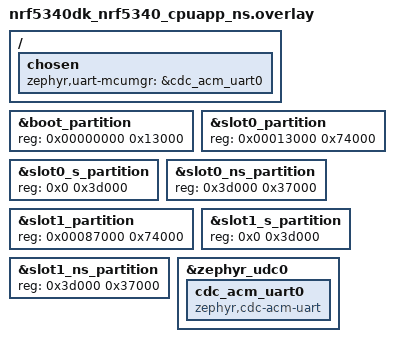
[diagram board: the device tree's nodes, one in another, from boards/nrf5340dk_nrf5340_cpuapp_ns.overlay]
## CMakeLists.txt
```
# SPDX-License-Identifier: Apache-2.0

cmake_minimum_required(VERSION 3.20.0)

find_package(Zephyr REQUIRED HINTS $ENV{ZEPHYR_BASE})
project(devacademy)

# STEP 6.1 - Include common files from Zephyr USB samples
include(${ZEPHYR_BASE}/samples/subsys/usb/common/common.cmake)

target_sources(app PRIVATE src/main.c)
```

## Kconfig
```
source "samples/subsys/usb/common/Kconfig.sample_usbd"

source "Kconfig.zephyr"
```

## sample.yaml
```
sample:
  description: nRF Connect SDK Intermediate Course by Nordic Developer Academy (https://academy.nordicsemi.com/)
  name: nRF Connect SDK Intermediate Course - Lesson 9 Exercise 4 Solution
  
common: 
    sysbuild: true
    harness: console
    harness_config:
      type: one_line
      regex:
        - "USB device support enabled"
    
tests:
  ncs_inter.l9.e4.sol:
    integration_platforms: 
      - nrf52833dk/nrf52833
      - nrf52840dk/nrf52840
      - nrf5340dk/nrf5340/cpuapp
      - nrf5340dk/nrf5340/cpuapp/ns
    platform_allow:
      - nrf52833dk/nrf52833
      - nrf52840dk/nrf52840
      - nrf5340dk/nrf5340/cpuapp
      - nrf5340dk/nrf5340/cpuapp/ns
    extra_args:
      - CONFIG_SAMPLE_USBD_PID=0x0001
      - CONFIG_SAMPLE_USBD_PRODUCT="USBD CDC ACM sample"

  ncs_inter.l9.e4.sol_lm20:
    integration_platforms: 
      - nrf54lm20dk/nrf54lm20a/cpuapp
    platform_allow:
      - nrf54lm20dk/nrf54lm20a/cpuapp        
```

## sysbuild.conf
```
# Add MCUboot
SB_CONFIG_BOOTLOADER_MCUBOOT=y
SB_CONFIG_MCUBOOT_USE_ALL_AVAILABLE_RAM=y

SB_CONFIG_PARTITION_MANAGER=n
```

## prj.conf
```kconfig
CONFIG_GPIO=y

# Enable MCUboot
CONFIG_BOOTLOADER_MCUBOOT=y

# Enable mcumgr DFU in application
CONFIG_MCUMGR=y

# Enable MCUMGR management for both OS and Images
CONFIG_MCUMGR_GRP_OS=y
CONFIG_MCUMGR_GRP_IMG=y

# Configure MCUMGR transport to UART
CONFIG_UART_MCUMGR=y
CONFIG_MCUMGR_TRANSPORT_UART=y


# Dependencies
# Configure dependencies for CONFIG_MCUMGR  
CONFIG_NET_BUF=y
CONFIG_ZCBOR=y
CONFIG_CRC=y

# Configure dependencies for CONFIG_MCUMGR_GRP_IMG  
CONFIG_FLASH=y
CONFIG_IMG_MANAGER=y

# Configure dependencies for CONFIG_IMG_MANAGER  
CONFIG_STREAM_FLASH=y
CONFIG_FLASH_MAP=y

# Configure dependencies for CONFIG_MCUMGR_TRANSPORT_UART 
CONFIG_BASE64=y

# STEP 5.3 - Enable USB subsystem
CONFIG_USB_DEVICE_STACK_NEXT=y
CONFIG_UART_USE_RUNTIME_CONFIGURE=y
CONFIG_UART_LINE_CTRL=y
CONFIG_USBD_CDC_ACM_CLASS=y


CONFIG_SAMPLE_USBD_PID=0x0001
CONFIG_SAMPLE_USBD_PRODUCT="USBD CDC ACM sample"
```

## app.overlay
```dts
/* STEP 5.2 - choose CDC ACM for mcumgr */
/ {
	chosen {
		zephyr,uart-mcumgr = &cdc_acm_uart0;
	};
};

/* STEP 5.1 - Configure CDC ACM */
&zephyr_udc0 {
	cdc_acm_uart0: cdc_acm_uart0 {
		compatible = "zephyr,cdc-acm-uart";
	};
};
```

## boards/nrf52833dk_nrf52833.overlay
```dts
/delete-node/ &slot1_partition;
/delete-node/ &slot0_partition;
/delete-node/ &storage_partition;

&flash0 {
	partitions {
		ranges;
		#address-cells = <1>;
		#size-cells = <1>;

		boot_partition: partition@0 {
			compatible = "zephyr,mapped-partition";
			label = "mcuboot";
			reg = <0x00000000 0x13000>;
		};

		slot0_partition: partition@13000 {
			compatible = "zephyr,mapped-partition";
			label = "image-0";
			reg = <0x00013000 0x17000>;
		};

		slot1_partition: partition@2a000 {
			compatible = "zephyr,mapped-partition";
			label = "image-1";
			reg = <0x0002a000 0x17000>;
		};

		storage_partition: partition@41000 {
			compatible = "zephyr,mapped-partition";
			label = "storage";
			reg = <0x00041000 0x00006000>;
		};
	};
};


/* STEP 5.2 - Choose CDC ACM for mcumgr */
/ {
	chosen {
		zephyr,uart-mcumgr = &cdc_acm_uart0;
	};
};

/* STEP 5.1 - Configure CDC ACM */
&zephyr_udc0 {
	cdc_acm_uart0: cdc_acm_uart0 {
		compatible = "zephyr,cdc-acm-uart";
	};
};
```

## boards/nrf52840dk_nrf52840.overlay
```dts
/delete-node/ &slot1_partition;
/delete-node/ &slot0_partition;
/delete-node/ &storage_partition;

&flash0 {
	partitions {
		ranges;
		#address-cells = <1>;
		#size-cells = <1>;

		boot_partition: partition@0 {
			compatible = "zephyr,mapped-partition";
			label = "mcuboot";
			reg = <0x00000000 0x00013000>;
		};

		slot0_partition: partition@13000 {
			compatible = "zephyr,mapped-partition";
			label = "image-0";
			reg = <0x00013000 0x00076000>;
		};

		slot1_partition: partition@89000 {
			compatible = "zephyr,mapped-partition";
			label = "image-1";
			reg = <0x00089000 0x00076000>;
		};

		/*
		 * The flash starting at 0x000f8000 and ending at
		 * 0x000fffff is reserved for use by the application.
		 */

		/*
		 * Storage partition will be used by FCB/LittleFS/NVS
		 * if enabled.
		 */
		storage_partition: partition@ff000 {
			compatible = "zephyr,mapped-partition";
			label = "storage";
			reg = <0x000ff000 0x00001000>;
		};
	};
};




/* STEP 5.2 - Choose CDC ACM for mcumgr */
/ {
	chosen {
		zephyr,uart-mcumgr = &cdc_acm_uart0;
	};
};

/* STEP 5.1 - Configure CDC ACM */
&zephyr_udc0 {
	cdc_acm_uart0: cdc_acm_uart0 {
		compatible = "zephyr,cdc-acm-uart";
	};
};
```

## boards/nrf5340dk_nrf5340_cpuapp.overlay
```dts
/delete-node/ &slot1_partition;
/delete-node/ &slot0_partition;
/delete-node/ &storage_partition;


&flash0 {
	partitions {
		ranges;
		#address-cells = <1>;
		#size-cells = <1>;

		boot_partition: partition@0 {
			compatible = "zephyr,mapped-partition";
			label = "mcuboot";
			reg = <0x00000000 0x13000>;
		};

		slot0_partition: partition@13000 {
			compatible = "zephyr,mapped-partition";
			label = "image-0";
			reg = <0x00013000 0x74000>;
		};

		slot1_partition: partition@87000 {
			compatible = "zephyr,mapped-partition";
			label = "image-1";
			reg = <0x00087000 0x74000>;
		};

	};
};


/ {
	chosen {
		zephyr,uart-mcumgr = &cdc_acm_uart0;
	};
};

&zephyr_udc0 {
	cdc_acm_uart0: cdc_acm_uart0 {
		compatible = "zephyr,cdc-acm-uart";
	};
};
```

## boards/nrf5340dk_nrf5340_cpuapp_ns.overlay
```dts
/delete-node/ &storage_partition;

&boot_partition {
	reg = <0x00000000 0x13000>;
};

&slot0_partition {
	reg = <0x00013000 0x74000>;
	ranges = <0x0 0x13000 0x74000>;
};

&slot0_s_partition {
	reg = <0x0 0x3d000>;
};

&slot0_ns_partition {
	reg = <0x3d000 0x37000>;
};

&slot1_partition {
	reg = <0x00087000 0x74000>;
	ranges = <0x0 0x87000 0x74000>;
};

&slot1_s_partition {
	reg = <0x0 0x3d000>;
};

&slot1_ns_partition {
	reg = <0x3d000 0x37000>;
};

/* STEP 5.2 - Choose CDC ACM for mcumgr */
/ {
	chosen {
		zephyr,uart-mcumgr = &cdc_acm_uart0;
	};
};

/* STEP 5.1 - Configure CDC ACM */
&zephyr_udc0 {
	cdc_acm_uart0: cdc_acm_uart0 {
		compatible = "zephyr,cdc-acm-uart";
	};
};
```

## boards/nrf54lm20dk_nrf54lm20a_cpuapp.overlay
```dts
/delete-node/ &boot_partition;
/delete-node/ &slot0_partition;
/delete-node/ &slot1_partition;

&cpuapp_rram {
    partitions {
        boot_partition: partition@0 {
            compatible = "zephyr,mapped-partition";
            label = "mcuboot";
            reg = <0x0 DT_SIZE_K(100)>;
        };

        slot0_partition: partition@19000 {
            compatible = "zephyr,mapped-partition";
            label = "image-0";
            reg = <0x19000 DT_SIZE_K(800)>;
        };

        slot1_partition: partition@e1000 {
            compatible = "zephyr,mapped-partition";
            label = "image-1";
            reg = <0xe1000 DT_SIZE_K(800)>;
        };
    };
};

/* CDC ACM for mcumgr (from app.overlay) */
/* STEP 5.2 - Choose CDC ACM for mcumgr */
/ {
    chosen {
        zephyr,uart-mcumgr = &cdc_acm_uart0;
    };
};

/* STEP 5.1 - Configure CDC ACM */
&zephyr_udc0 {
    cdc_acm_uart0: cdc_acm_uart0 {
        compatible = "zephyr,cdc-acm-uart";
    };
};
```

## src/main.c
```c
/*
 * Copyright (c) 2016 Intel Corporation
 *
 * SPDX-License-Identifier: Apache-2.0
 */

#include <zephyr/kernel.h>
#include <zephyr/drivers/gpio.h>

/* STEP 7.1 - Include header for USB */
#include <sample_usbd.h>

#include <zephyr/logging/log.h>
LOG_MODULE_REGISTER(usb_cdc, LOG_LEVEL_INF);

/* 1000 msec = 1 sec */

#define SLEEP_TIME_MS 1000

/* The devicetree node identifier for the "led0" alias. */
#define LED0_NODE DT_ALIAS(led0)

/*
 * A build error on this line means your board is unsupported.
 * See the sample documentation for information on how to fix this.
 */
static const struct gpio_dt_spec led = GPIO_DT_SPEC_GET(LED0_NODE, gpios);

/* STEP 7.2 - Create context for USB stack */
static struct usbd_context *sample_usbd;

/* STEP 7.3 - Create VBUS callback function */
static void sample_msg_cb(struct usbd_context *const ctx, const struct usbd_msg *msg)
{
    LOG_INF("USBD message: %s", usbd_msg_type_string(msg->type));

    if (usbd_can_detect_vbus(ctx)) {
        if (msg->type == USBD_MSG_VBUS_READY) {
            if (usbd_enable(ctx)) {
                LOG_ERR("Failed to enable device support");
            }
        }

        if (msg->type == USBD_MSG_VBUS_REMOVED) {
            if (usbd_disable(ctx)) {
                LOG_ERR("Failed to disable device support");
            }
        }
    }
}


int main(void)
{
    int ret;

    /* STEP 7.4 - Initialize usb device */
    sample_usbd = sample_usbd_init_device(sample_msg_cb);
    if (sample_usbd == NULL) {
        LOG_ERR("Failed to initialize USB device");
        return -ENODEV;
    }

    /* STEP 7.5 - Enable usb device in case vbus not detected */
    if (!usbd_can_detect_vbus(sample_usbd)) {
        ret = usbd_enable(sample_usbd);
        if (ret) {
            LOG_ERR("Failed to enable device support");
            return ret;
        }
    }

    LOG_INF("USB device support enabled");

    if (!device_is_ready(led.port)) {
        return 0;
    }

    ret = gpio_pin_configure_dt(&led, GPIO_OUTPUT_ACTIVE);
    if (ret < 0) {
        return 0;
    }

    while (1) {
        ret = gpio_pin_toggle_dt(&led);
        if (ret < 0) {
            return 0;
        }
        k_msleep(SLEEP_TIME_MS);
    }
    return 1;
}
```
